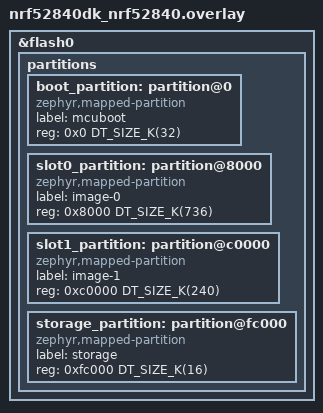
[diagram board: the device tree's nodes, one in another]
/*
 * Copyright (c) 2026 Nordic Semiconductor ASA
 *
 * SPDX-License-Identifier: LicenseRef-Nordic-5-Clause
 */

/delete-node/ &boot_partition;
/delete-node/ &slot0_partition;
/delete-node/ &slot1_partition;
/delete-node/ &storage_partition;

&flash0 {
	partitions {
		boot_partition: partition@0 {
			compatible = "zephyr,mapped-partition";
			label = "mcuboot";
			reg = <0x0 DT_SIZE_K(32)>;
		};

		slot0_partition: partition@8000 {
			compatible = "zephyr,mapped-partition";
			label = "image-0";
			reg = <0x8000 DT_SIZE_K(736)>;
		};

		slot1_partition: partition@c0000 {
			compatible = "zephyr,mapped-partition";
			label = "image-1";
			reg = <0xc0000 DT_SIZE_K(240)>;
		};

		storage_partition: partition@fc000 {
			compatible = "zephyr,mapped-partition";
			label = "storage";
			reg = <0xfc000 DT_SIZE_K(16)>;
		};
	};
};
